# S32M24x register map
Vendor: NXP Semiconductors; File version: 1.5
CPU: CM4 r0p1, little endian, MPU, FPU, VTOR, 4 interrupt priority bits
Registers are 32-bit, read-write, reset 0x0 unless marked. A register's access mark holds for its fields unless they carry their own. Offsets are from the block's base; [hi:lo] are bit positions; {n}, {i} and the like mark numbered series; 'fields as' and 'values as' point back to an identical list.

## PCC
Base 0x40065000
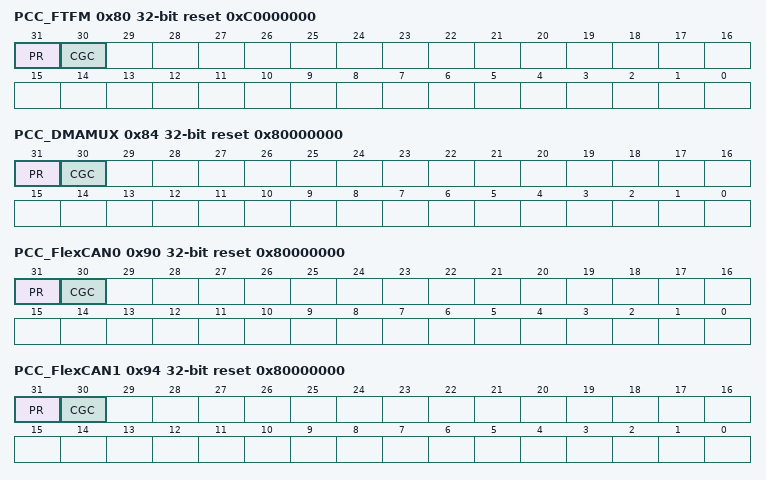
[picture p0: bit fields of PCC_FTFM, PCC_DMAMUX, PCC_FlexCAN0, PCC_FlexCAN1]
0x80 PCC_FTFM reset 0xC0000000
  [31] PR ro — Present
    0=NOT_PRESENT (Peripheral is not present.); 1=PRESENT (Peripheral is present.)
  [30] CGC — Clock Gate Control
    0=DISABLED (Clock disabled. The current clock selection and divider options are not locked and can be modified.); 1=ENABLED (Clock enabled. The current clock selection and divider options are locked and cannot be modified.)
0x84 PCC_DMAMUX reset 0x80000000
  fields as PCC_FTFM
0x90 PCC_FlexCAN0 reset 0x80000000
  fields as PCC_FTFM
0x94 PCC_FlexCAN1 reset 0x80000000
  fields as PCC_FTFM
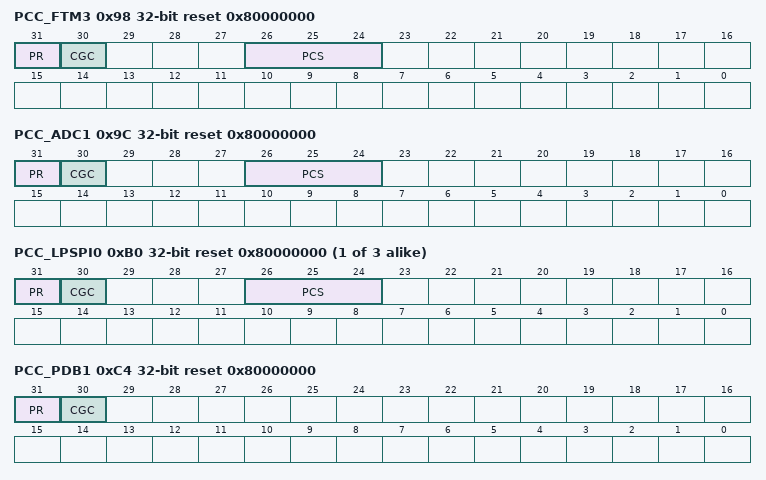
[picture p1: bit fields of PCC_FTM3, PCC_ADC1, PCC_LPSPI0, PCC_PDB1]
0x98 PCC_FTM3 reset 0x80000000
  [31] PR ro — Present
    values as PCC_FTFM.PR
  [30] CGC — Clock Gate Control
    values as PCC_FTFM.CGC
  [26:24] PCS — Peripheral Clock Source Select
    0=CLOCK_EXT (Clock is off. An external clock can be enabled for this peripheral.); {v}=CLOCK_OPT{v} (Clock option {v}) (v=1..7)
0x9C PCC_ADC1 reset 0x80000000
  [31] PR ro — Present
    values as PCC_FTFM.PR
  [30] CGC — Clock Gate Control
    values as PCC_FTFM.CGC
  [26:24] PCS — Peripheral Clock Source Select
    0=CLOCK_OFF (Clock is off.); {v}=CLOCK_OPT{v} (Clock option {v}) (v=1..7)
{0xB0+4i} PCC_LPSPI{i} reset 0x80000000 (i=0..2)
  fields as PCC_ADC1
0xC4 PCC_PDB1 reset 0x80000000
  fields as PCC_FTFM
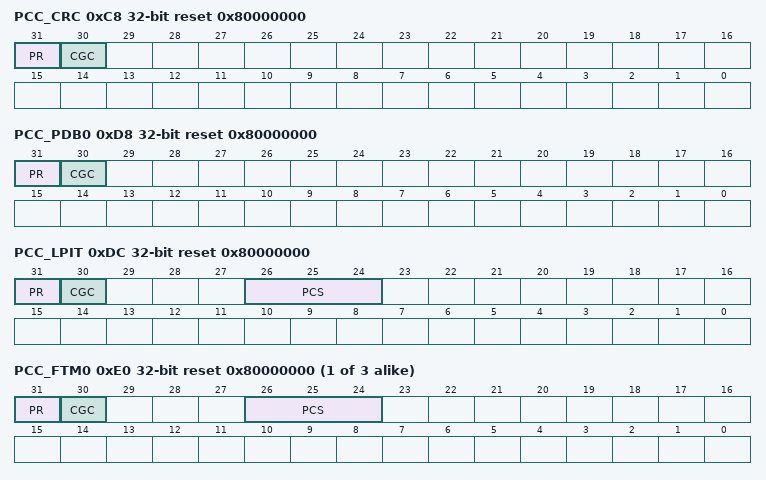
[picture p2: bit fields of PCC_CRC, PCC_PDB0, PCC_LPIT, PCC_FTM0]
0xC8 PCC_CRC reset 0x80000000
  fields as PCC_FTFM
0xD8 PCC_PDB0 reset 0x80000000
  fields as PCC_FTFM
0xDC PCC_LPIT reset 0x80000000
  fields as PCC_ADC1
{0xE0+4i} PCC_FTM{i} reset 0x80000000 (i=0..2)
  fields as PCC_FTM3
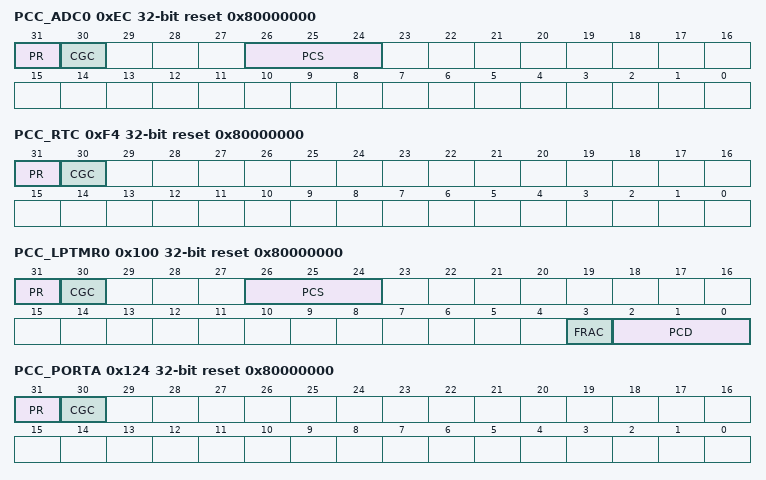
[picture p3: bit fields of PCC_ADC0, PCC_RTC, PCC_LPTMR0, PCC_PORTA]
0xEC PCC_ADC0 reset 0x80000000
  fields as PCC_ADC1
0xF4 PCC_RTC reset 0x80000000
  fields as PCC_FTFM
0x100 PCC_LPTMR0 reset 0x80000000
  [31] PR ro — Present
    values as PCC_FTFM.PR
  [30] CGC — Clock Gate Control
    values as PCC_FTFM.CGC
  [26:24] PCS — Peripheral Clock Source Select
    values as PCC_ADC1.PCS
  [3] FRAC — Peripheral Clock Divider Fraction
    0=Fractional value is 0; 1=Fractional value is 1
  [2:0] PCD — Peripheral Clock Divider Select
    {v}=DIV_{v+1} (Divide by {v+1}.) (v=0..7)
0x124 PCC_PORTA reset 0x80000000
  fields as PCC_FTFM
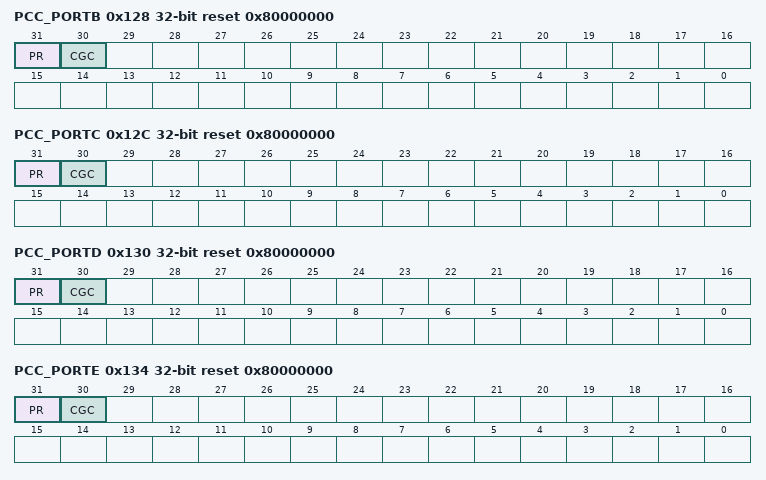
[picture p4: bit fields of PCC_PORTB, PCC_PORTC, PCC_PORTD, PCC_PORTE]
0x128 PCC_PORTB reset 0x80000000
  fields as PCC_FTFM
0x12C PCC_PORTC reset 0x80000000
  fields as PCC_FTFM
0x130 PCC_PORTD reset 0x80000000
  fields as PCC_FTFM
0x134 PCC_PORTE reset 0x80000000
  fields as PCC_FTFM
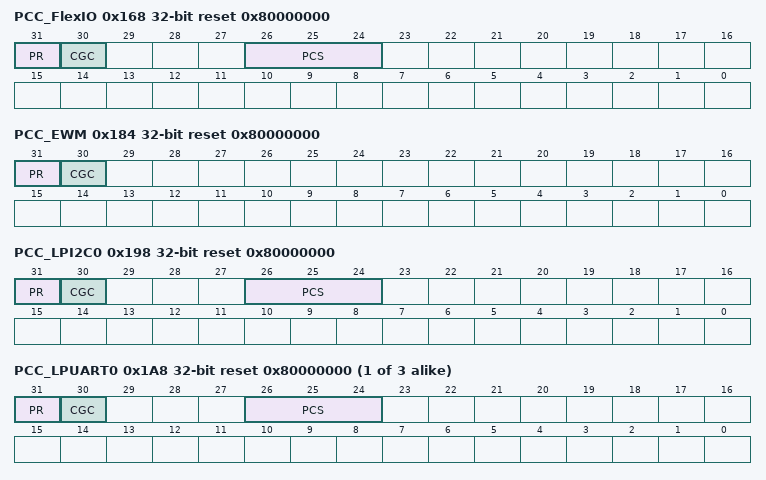
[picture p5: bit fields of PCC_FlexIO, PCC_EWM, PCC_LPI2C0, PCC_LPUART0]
0x168 PCC_FlexIO reset 0x80000000
  fields as PCC_ADC1
0x184 PCC_EWM reset 0x80000000
  fields as PCC_FTFM
0x198 PCC_LPI2C0 reset 0x80000000
  fields as PCC_ADC1
{0x1A8+4i} PCC_LPUART{i} reset 0x80000000 (i=0..2)
  fields as PCC_ADC1
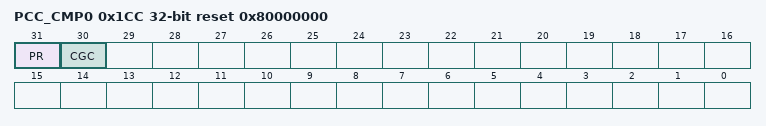
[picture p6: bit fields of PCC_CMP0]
0x1CC PCC_CMP0 reset 0x80000000
  fields as PCC_FTFM

## PMC
Base 0x4007D000
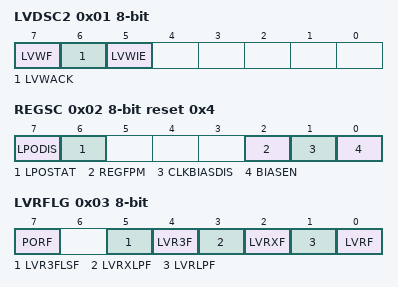
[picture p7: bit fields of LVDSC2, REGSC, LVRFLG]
0x01 LVDSC2 8-bit — Low Voltage Detect Status and Control 2 Register
  [7] LVWF ro — Low-Voltage Warning Flag
    0=Low-voltage warning event not detected; 1=Low-voltage warning event detected
  [6] LVWACK wo — Low-Voltage Warning Acknowledge
  [5] LVWIE — Low-Voltage Warning Interrupt Enable
    0=Hardware interrupt disabled (use polling); 1=Request a hardware interrupt when LVWF=1
0x02 REGSC 8-bit reset 0x4 (reset mask 0xBF) — Regulator Status and Control Register
  [7] LPODIS — LPO Disable Bit
    0=Low power oscillator enabled; 1=Low power oscillator disabled
  [6] LPOSTAT ro — LPO Status Bit
    0=Low power oscillator in low phase; 1=Low power oscillator in high phase
  [2] REGFPM ro — Regulator in Full Performance Mode Status Bit
    0=Regulator is in low power mode or transition to/from; 1=Regulator is in full performance mode
  [1] CLKBIASDIS — Clock Bias Disable Bit
    0=No effect; 1=In VLPS mode, the bias currents and reference voltages for the following clock modules are disabled: SIRC, FIRC, PLL. (if available on device)
  [0] BIASEN — Bias Enable Bit
    0=Biasing disabled, core logic can run in full performance; 1=Biasing enabled, core logic is slower and there are restrictions in allowed system clock speed (see Data Sheet for details)
0x03 LVRFLG 8-bit (reset mask 0x40) write-1-clears — Low Voltage Reset Flags Register
  [7] PORF write-1-clears — POR Flag
  [5] LVR3FLSF write-1-clears — LVR 3V Flash memory Flag
  [4] LVR3F write-1-clears — LVR 3V Flag
  [3] LVRXLPF write-1-clears — LVR external in low power mode flag
  [2] LVRXF write-1-clears — LVR External Flag
  [1] LVRLPF write-1-clears — LVR in low power mode core Flag
  [0] LVRF write-1-clears — LVR Core Flag
0x04 LPOTRIM 8-bit (reset mask 0xE0) — Low Power Oscillator Trim Register
  [4:0] LPOTRIM — LPO trimming bits

## PMC_142 — PMC
Base 0x4007D000; alternate view of PMC
Registers as PMC, without LVRFLG; these are added or differ:
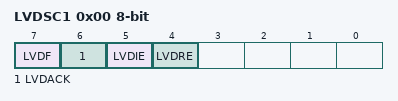
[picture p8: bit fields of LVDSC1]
0x00 LVDSC1 8-bit (reset mask 0xEF) — Low Voltage Detect Status and Control 1 Register
  [7] LVDF ro — Low Voltage Detect Flag
    0=Low-voltage event not detected; 1=Low-voltage event detected
  [6] LVDACK wo — Low Voltage Detect Acknowledge
  [5] LVDIE — Low Voltage Detect Interrupt Enable
    0=Hardware interrupt disabled (use polling); 1=Request a hardware interrupt when LVDF = 1
  [4] LVDRE — Low Voltage Detect Reset Enable
    0=No system resets on low voltage detect events; 1=If the supply voltage falls below VLVD, a system reset will be generated
